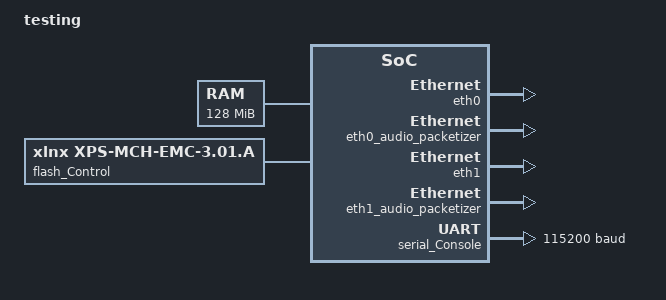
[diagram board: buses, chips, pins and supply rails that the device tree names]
/*
 * Device Tree Generator version: 1.3
 *
 * (C) Copyright 2007-2008 Xilinx, Inc.
 * (C) Copyright 2007-2009 Michal Simek
 *
 * Michal SIMEK <monstr@monstr.eu>
 *
 * This program is free software; you can redistribute it and/or
 * modify it under the terms of the GNU General Public License as
 * published by the Free Software Foundation; either version 2 of
 * the License, or (at your option) any later version.
 *
 * This program is distributed in the hope that it will be useful,
 * but WITHOUT ANY WARRANTY; without even the implied warranty of
 * MERCHANTABILITY or FITNESS FOR A PARTICULAR PURPOSE. See the
 * GNU General Public License for more details.
 *
 * You should have received a copy of the GNU General Public License
 * along with this program; if not, write to the Free Software
 * Foundation, Inc., 59 Temple Place, Suite 330, Boston,
 * MA 02111-1307 USA
 *
 * CAUTION: This file is automatically generated by libgen.
 * Version: Xilinx EDK 12.1 EDK_MS1.53d
 *
 * XPS project directory: device-tree_bsp_0
 */

/dts-v1/;
/ {
	#address-cells = <1>;
	#size-cells = <1>;
	compatible = "xlnx,microblaze";
	model = "testing";
	aliases {
		ethernet0 = &eth0;
		ethernet1 = &eth1;
		serial0 = &serial_Console;
	} ;
	chosen {
		bootargs = "console=ttyUL0 mtdparts=87000000.flash:2048K(fpga),256K(boot),128K(fdt),5760K(image),6016K(romfs),2048K(settingsfs),32K(bootenv) root=mtd7 rootfstype=romfs";
		linux,stdout-path = "/plb@0/serial@82020000";
	} ;
	cpus {
		#address-cells = <1>;
		#cpus = <0x1>;
		#size-cells = <0>;
		microblaze_0: cpu@0 {
			clock-frequency = <62500000>;
			compatible = "xlnx,microblaze-7.30.a";
			d-cache-baseaddr = <0x88000000>;
			d-cache-highaddr = <0x8fffffff>;
			d-cache-line-size = <0x10>;
			d-cache-size = <0x2000>;
			device_type = "cpu";
			i-cache-baseaddr = <0x88000000>;
			i-cache-highaddr = <0x8fffffff>;
			i-cache-line-size = <0x10>;
			i-cache-size = <0x2000>;
			model = "microblaze,7.30.a";
			reg = <0>;
			timebase-frequency = <62500000>;
			xlnx,addr-tag-bits = <0xe>;
			xlnx,allow-dcache-wr = <0x1>;
			xlnx,allow-icache-wr = <0x1>;
			xlnx,archiver = "0";
			xlnx,area-optimized = <0x0>;
			xlnx,branch-target-cache-size = <0x0>;
			xlnx,cache-byte-size = <0x2000>;
			xlnx,compiler = "0";
			xlnx,compiler-flags = "0";
			xlnx,core-clock-freq-hz = <0x5f5e100>;
			xlnx,d-lmb = <0x1>;
			xlnx,d-plb = <0x1>;
			xlnx,data-size = <0x20>;
			xlnx,dcache-addr-tag = <0xe>;
			xlnx,dcache-always-used = <0x1>;
			xlnx,dcache-byte-size = <0x2000>;
			xlnx,dcache-interface = <0x0>;
			xlnx,dcache-line-len = <0x4>;
			xlnx,dcache-use-fsl = <0x1>;
			xlnx,dcache-use-writeback = <0x0>;
			xlnx,dcache-victims = <0x0>;
			xlnx,debug-enabled = <0x1>;
			xlnx,div-zero-exception = <0x1>;
			xlnx,dynamic-bus-sizing = <0x1>;
			xlnx,edge-is-positive = <0x1>;
			xlnx,extra-compiler-flags = "0";
			xlnx,family = "spartan6";
			xlnx,fpu-exception = <0x0>;
			xlnx,freq = <0x3b9aca0>;
			xlnx,fsl-data-size = <0x20>;
			xlnx,fsl-exception = <0x0>;
			xlnx,fsl-links = <0x0>;
			xlnx,i-lmb = <0x1>;
			xlnx,i-plb = <0x1>;
			xlnx,icache-always-used = <0x1>;
			xlnx,icache-interface = <0x0>;
			xlnx,icache-line-len = <0x4>;
			xlnx,icache-streams = <0x0>;
			xlnx,icache-use-fsl = <0x1>;
			xlnx,icache-victims = <0x0>;
			xlnx,ill-opcode-exception = <0x1>;
			xlnx,instance = "microblaze_0";
			xlnx,interconnect = <0x1>;
			xlnx,interrupt-is-edge = <0x0>;
			xlnx,mmu-dtlb-size = <0x4>;
			xlnx,mmu-itlb-size = <0x2>;
			xlnx,mmu-tlb-access = <0x3>;
			xlnx,mmu-zones = <0x10>;
			xlnx,multiplier = "false";
			xlnx,number-of-pc-brk = <0x2>;
			xlnx,number-of-rd-addr-brk = <0x0>;
			xlnx,number-of-wr-addr-brk = <0x0>;
			xlnx,opcode-0x0-illegal = <0x1>;
			xlnx,optimization = <0x0>;
			xlnx,pvr = <0x0>;
			xlnx,pvr-user1 = <0x0>;
			xlnx,pvr-user2 = <0x0>;
			xlnx,reset-msr = <0x0>;
			xlnx,sco = <0x0>;
			xlnx,unaligned-exceptions = <0x1>;
			xlnx,use-barrel = <0x1>;
			xlnx,use-branch-target-cache = <0x0>;
			xlnx,use-dcache = <0x1>;
			xlnx,use-div = <0x1>;
			xlnx,use-ext-brk = <0x1>;
			xlnx,use-ext-nm-brk = <0x1>;
			xlnx,use-extended-fsl-instr = <0x0>;
			xlnx,use-fpu = <0x0>;
			xlnx,use-hw-mul = <0x1>;
			xlnx,use-icache = <0x1>;
			xlnx,use-interrupt = <0x1>;
			xlnx,use-mmu = <0x0>;
			xlnx,use-msr-instr = <0x1>;
			xlnx,use-pcmp-instr = <0x1>;
			xlnx,xmdstub-peripheral = "false";
		} ;
	} ;
	ddr2_Control: memory@88000000 {
		device_type = "memory";
		reg = < 0x88000000 0x8000000 >;
	} ;
	peripheral_Bus: plb@0 {
		#address-cells = <1>;
		#size-cells = <1>;
		compatible = "xlnx,plb-v46-1.04.a", "xlnx,plb-v46-1.00.a", "simple-bus";
		ranges ;
		eth0: ethernet@82050000 {
			compatible = "xlnx,labx-ethernet-1.00.a";
			device_type = "network";
			interrupt-parent = <&irq_Control>;
			interrupts = < 3 2 2 2 >;
			local-mac-address = [ 00 0a 35 5e 19 00 ];
			phy-mdio-controller = <&eth0>;
			reg = < 0x82050000 0x1000 >;
			xlnx,has-mdio = <0x1>;
			xlnx,phy-addr = <0x1>;
			xlnx,phy-mask = <0xffff>;
			xlnx,phy-type = <0x1>;
			xlnx,rxcsum = <0x0>;
			xlnx,txcsum = <0x0>;
		} ;
		eth0_audio_packetizer: labrinth-avb-packetizer@82090000 {
			compatible = "xlnx,labrinth-avb-packetizer-1.00.a";
			interrupt-parent = <&irq_Control>;
			interrupts = < 8 2 >;
			reg = < 0x82090000 0x10000 >;
			xlnx,device = "6slx45";
			xlnx,family = "spartan6";
			xlnx,include-dphase-timer = <0x0>;
			xlnx,package = "csg324";
		} ;
		eth1: ethernet@82070000 {
			compatible = "xlnx,labx-ethernet-1.00.a";
			device_type = "network";
			interrupt-parent = <&irq_Control>;
			interrupts = < 5 2 4 2 >;
			local-mac-address = [ 00 0a 35 5e 9b 01 ];
			phy-mdio-controller = <&eth0>;
			reg = < 0x82070000 0x1000 >;
			xlnx,has-mdio = <0x0>;
			xlnx,phy-addr = <0x2>;
			xlnx,phy-mask = <0xffff>;
			xlnx,phy-type = <0x1>;
			xlnx,rxcsum = <0x0>;
			xlnx,txcsum = <0x0>;
		} ;
		eth1_audio_packetizer: labrinth-avb-packetizer@820a0000 {
			compatible = "xlnx,labrinth-avb-packetizer-1.00.a";
			interrupt-parent = <&irq_Control>;
			interrupts = < 9 2 >;
			reg = < 0x820a0000 0x10000 >;
			xlnx,device = "6slx45";
			xlnx,family = "spartan6";
			xlnx,include-dphase-timer = <0x0>;
			xlnx,package = "csg324";
		} ;
		flash_Control: flash@87000000 {
			bank-width = <2>;
			compatible = "xlnx,xps-mch-emc-3.01.a", "cfi-flash";
			reg = < 0x87000000 0x1000000 >;
			xlnx,family = "spartan6";
			xlnx,include-datawidth-matching-0 = <0x1>;
			xlnx,include-datawidth-matching-1 = <0x0>;
			xlnx,include-datawidth-matching-2 = <0x0>;
			xlnx,include-datawidth-matching-3 = <0x0>;
			xlnx,include-negedge-ioregs = <0x0>;
			xlnx,include-plb-ipif = <0x1>;
			xlnx,include-wrbuf = <0x1>;
			xlnx,max-mem-width = <0x10>;
			xlnx,mch-native-dwidth = <0x20>;
			xlnx,mch-splb-awidth = <0x20>;
			xlnx,mch-splb-clk-period-ps = <0x3e80>;
			xlnx,mch0-accessbuf-depth = <0x10>;
			xlnx,mch0-protocol = <0x0>;
			xlnx,mch0-rddatabuf-depth = <0x10>;
			xlnx,mch1-accessbuf-depth = <0x10>;
			xlnx,mch1-protocol = <0x0>;
			xlnx,mch1-rddatabuf-depth = <0x10>;
			xlnx,mch2-accessbuf-depth = <0x10>;
			xlnx,mch2-protocol = <0x0>;
			xlnx,mch2-rddatabuf-depth = <0x10>;
			xlnx,mch3-accessbuf-depth = <0x10>;
			xlnx,mch3-protocol = <0x0>;
			xlnx,mch3-rddatabuf-depth = <0x10>;
			xlnx,mem0-width = <0x10>;
			xlnx,mem1-width = <0x20>;
			xlnx,mem2-width = <0x20>;
			xlnx,mem3-width = <0x20>;
			xlnx,num-banks-mem = <0x1>;
			xlnx,num-channels = <0x0>;
			xlnx,pagemode-flash-0 = <0x0>;
			xlnx,pagemode-flash-1 = <0x0>;
			xlnx,pagemode-flash-2 = <0x0>;
			xlnx,pagemode-flash-3 = <0x0>;
			xlnx,priority-mode = <0x0>;
			xlnx,synch-mem-0 = <0x0>;
			xlnx,synch-mem-1 = <0x0>;
			xlnx,synch-mem-2 = <0x0>;
			xlnx,synch-mem-3 = <0x0>;
			xlnx,synch-pipedelay-0 = <0x2>;
			xlnx,synch-pipedelay-1 = <0x2>;
			xlnx,synch-pipedelay-2 = <0x2>;
			xlnx,synch-pipedelay-3 = <0x2>;
			xlnx,tavdv-ps-mem-0 = <0x11170>;
			xlnx,tavdv-ps-mem-1 = <0x3a98>;
			xlnx,tavdv-ps-mem-2 = <0x3a98>;
			xlnx,tavdv-ps-mem-3 = <0x3a98>;
			xlnx,tcedv-ps-mem-0 = <0x11170>;
			xlnx,tcedv-ps-mem-1 = <0x3a98>;
			xlnx,tcedv-ps-mem-2 = <0x3a98>;
			xlnx,tcedv-ps-mem-3 = <0x3a98>;
			xlnx,thzce-ps-mem-0 = <0x61a8>;
			xlnx,thzce-ps-mem-1 = <0x1b58>;
			xlnx,thzce-ps-mem-2 = <0x1b58>;
			xlnx,thzce-ps-mem-3 = <0x1b58>;
			xlnx,thzoe-ps-mem-0 = <0x61a8>;
			xlnx,thzoe-ps-mem-1 = <0x1b58>;
			xlnx,thzoe-ps-mem-2 = <0x1b58>;
			xlnx,thzoe-ps-mem-3 = <0x1b58>;
			xlnx,tlzwe-ps-mem-0 = <0x1388>;
			xlnx,tlzwe-ps-mem-1 = <0x0>;
			xlnx,tlzwe-ps-mem-2 = <0x0>;
			xlnx,tlzwe-ps-mem-3 = <0x0>;
			xlnx,tpacc-ps-flash-0 = <0x61a8>;
			xlnx,tpacc-ps-flash-1 = <0x61a8>;
			xlnx,tpacc-ps-flash-2 = <0x61a8>;
			xlnx,tpacc-ps-flash-3 = <0x61a8>;
			xlnx,twc-ps-mem-0 = <0x11170>;
			xlnx,twc-ps-mem-1 = <0x3a98>;
			xlnx,twc-ps-mem-2 = <0x3a98>;
			xlnx,twc-ps-mem-3 = <0x3a98>;
			xlnx,twp-ps-mem-0 = <0xafc8>;
			xlnx,twp-ps-mem-1 = <0x2ee0>;
			xlnx,twp-ps-mem-2 = <0x2ee0>;
			xlnx,twp-ps-mem-3 = <0x2ee0>;
			xlnx,xcl0-linesize = <0x4>;
			xlnx,xcl0-writexfer = <0x1>;
			xlnx,xcl1-linesize = <0x4>;
			xlnx,xcl1-writexfer = <0x1>;
			xlnx,xcl2-linesize = <0x4>;
			xlnx,xcl2-writexfer = <0x1>;
			xlnx,xcl3-linesize = <0x4>;
			xlnx,xcl3-writexfer = <0x1>;
		} ;
		irq_Control: interrupt-controller@82000000 {
			#interrupt-cells = <0x2>;
			compatible = "xlnx,xps-intc-2.01.a", "xlnx,xps-intc-1.00.a";
			interrupt-controller ;
			reg = < 0x82000000 0x10000 >;
			xlnx,kind-of-intr = <0xc1>;
			xlnx,num-intr-inputs = <0xa>;
		} ;
		labx_ptp0: labx-ptp@82080000 {
			compatible = "xlnx,labx-ptp-1.00.a";
			interrupt-parent = <&irq_Control>;
			interrupts = < 1 2 >;
			port-interface-0 = <&eth0>;
			port-interface-1 = <&eth1>;
			reg = < 0x82080000 0x10000 >;
			xlnx,extra-dsp = <0x0>;
			xlnx,family = "spartan6";
			xlnx,include-dphase-timer = <0x0>;
			xlnx,num-ports = <0x2>;
			xlnx,port-interface-0 = "eth0";
			xlnx,port-interface-1 = "eth1";
			xlnx,port-interface-2 = "Invalid";
			xlnx,port-interface-3 = "Invalid";
			xlnx,port-interface-4 = "Invalid";
			xlnx,port-interface-5 = "Invalid";
			xlnx,port-interface-6 = "Invalid";
			xlnx,port-interface-7 = "Invalid";
		} ;
		mdm_0: debug@82010000 {
			compatible = "xlnx,mdm-1.00.g";
			interrupt-parent = <&irq_Control>;
			interrupts = < 6 0 >;
			reg = < 0x82010000 0x10000 >;
			xlnx,family = "spartan6";
			xlnx,interconnect = <0x1>;
			xlnx,jtag-chain = <0x2>;
			xlnx,mb-dbg-ports = <0x1>;
			xlnx,uart-width = <0x8>;
			xlnx,use-uart = <0x1>;
			xlnx,write-fsl-ports = <0x0>;
		} ;
		serial_Console: serial@82020000 {
			clock-frequency = <62500000>;
			compatible = "xlnx,xps-uartlite-1.01.a", "xlnx,xps-uartlite-1.00.a";
			current-speed = <115200>;
			device_type = "serial";
			interrupt-parent = <&irq_Control>;
			interrupts = < 7 0 >;
			port-number = <0>;
			reg = < 0x82020000 0x10000 >;
			xlnx,baudrate = <0x1c200>;
			xlnx,data-bits = <0x8>;
			xlnx,family = "spartan6";
			xlnx,odd-parity = <0x1>;
			xlnx,use-parity = <0x0>;
		} ;
		system_Timer: timer@82030000 {
			compatible = "xlnx,xps-timer-1.02.a", "xlnx,xps-timer-1.00.a";
			interrupt-parent = <&irq_Control>;
			interrupts = < 0 0 >;
			reg = < 0x82030000 0x10000 >;
			xlnx,count-width = <0x20>;
			xlnx,family = "spartan6";
			xlnx,gen0-assert = <0x1>;
			xlnx,gen1-assert = <0x1>;
			xlnx,one-timer-only = <0x0>;
			xlnx,trig0-assert = <0x1>;
			xlnx,trig1-assert = <0x1>;
		} ;
	} ;
}  ;
